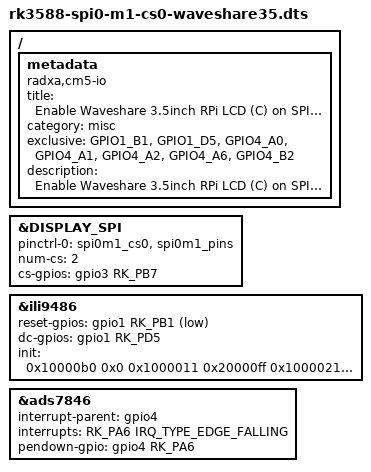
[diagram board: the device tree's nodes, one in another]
#define DISPLAY_SPI spi0
#include "waveshare35-lcd.dtsi"

/ {
	metadata {
		title = "Enable Waveshare 3.5inch RPi LCD (C) on SPI0-M0";
		compatible = "radxa,cm5-io";
		category = "misc";
		exclusive = "GPIO1_B1", "GPIO1_D5", "GPIO4_A0", "GPIO4_A1", "GPIO4_A2", "GPIO4_A6", "GPIO4_B2" ;
		description = "Enable Waveshare 3.5inch RPi LCD (C) on SPI0-M0.
Touch is temporarily unavailable.";
	};
};

&DISPLAY_SPI {
	pinctrl-names = "default";
	pinctrl-0 = <&spi0m1_cs0 &spi0m1_pins>;
	num-cs = <2>;
	cs-gpios = <&gpio3 RK_PB7 GPIO_ACTIVE_HIGH>;
};

&ili9486 {
	reset-gpios = <&gpio1 RK_PB1 GPIO_ACTIVE_LOW>; // GPIO1_B1
	dc-gpios = <&gpio1 RK_PD5 GPIO_ACTIVE_HIGH>; // GPIO1_D5

	init = <0x10000b0 0x0
			0x1000011
			0x20000ff
			0x1000021
			0x100003a 0x55
			0x10000c2 0x33
			0x10000c5 0x0 0x1e 0x80
			0x1000036 0x28
			0x10000b1 0xb0
			0x10000e0 0x0 0x13 0x18 0x4 0xf 0x6 0x3a 0x56 0x4d 0x3 0xa 0x6 0x30 0x3e 0xf
			0x10000e1 0x0 0x13 0x18 0x1 0x11 0x6 0x38 0x34 0x4d 0x6 0xd 0xb 0x31 0x37 0xf
			0x1000011
			0x20000ff
			0x1000029>;
};

&ads7846 {
	interrupt-parent = <&gpio4>;
	interrupts = <RK_PA6 IRQ_TYPE_EDGE_FALLING>;
	pendown-gpio = <&gpio4 RK_PA6 GPIO_ACTIVE_HIGH>;
};
